# RN8XXX_V2 register map
File version: 1.0
Registers are 32-bit, read-write, reset 0x0 unless marked. A register's access mark holds for its fields unless they carry their own. Offsets are from the block's base; [hi:lo] are bit positions; {n}, {i} and the like mark numbered series; 'fields as' and 'values as' point back to an identical list.

## SYSTEM_CONTROL
Base 0x40034000
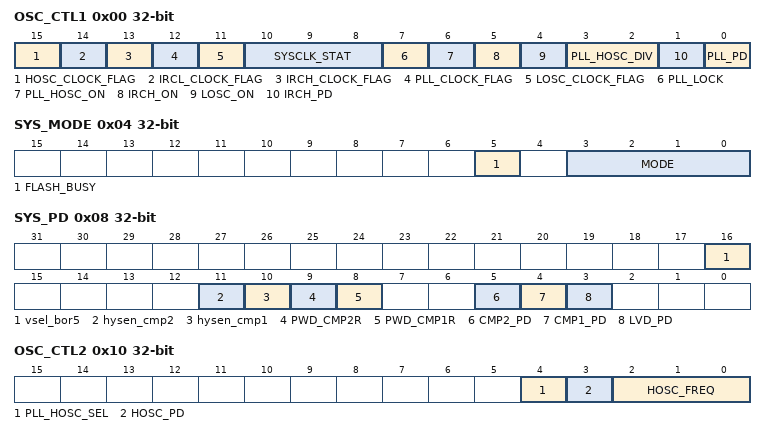
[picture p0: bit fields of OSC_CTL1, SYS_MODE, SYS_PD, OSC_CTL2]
0x00 OSC_CTL1 — system oscillator control No.1
  [15] HOSC_CLOCK_FLAG ro — HOSC on status
    0=off (HOSC stops); 1=on (HOSC running)
  [14] IRCL_CLOCK_FLAG ro — IRCL on status
    0=off (IRCL stops); 1=on (IRCL running)
  [13] IRCH_CLOCK_FLAG ro — IRCH on status
    0=off (IRCH stops); 1=on (IRCH running)
  [12] PLL_CLOCK_FLAG ro — PLL on status
    0=off (PLL stops); 1=on (PLL running)
  [11] LOSC_CLOCK_FLAG ro — LOSC on status
    0=off (LOSC stops); 1=on (LOSC running)
  [10:8] SYSCLK_STAT ro — system clock selection status
    0=7.8432MHz (system clock running at 7.8432MHz); 1=3.6864MHz (system clock running at 3.6864MHz); 2=1.8432MHz (system clock running at 1.8432MHz); 3=32.768KHz (system clock running at 32.768KHz); 4=14.7456MHz (system clock running at 14.7456MHz); 5=29.4912MHz (system clock running at 29.4912MHz)
  [7] PLL_LOCK ro — PLL locked status
    0=not_locked (PLL hasn't locked yet); 1=locked (PLL locked)
  [6] PLL_HOSC_ON ro — system clock indicator as external high-frequence oscillator or internal PLL
    0=not_PLL_HOSC (PLL_HOSC isn't used as system clock); 1=PLL_HOSC (PLL_HOSC used as system clock)
  [5] IRCH_ON ro — system clock indicator as internal RC oscillator
    0=not_IRCH (IRCH isn't used as system clock); 1=IRCH (IRCH used as system clock)
  [4] LOSC_ON ro — system clock indicator as external low-frequence oscillator
    0=not_LOSC (losc isn't used as system clock); 1=LOSC (losc used as system clock)
  [3:2] PLL_HOSC_DIV — system clock divisor(applicable for high frequency mode(PLL or HOSC))
    0=use PLL or HOSC as system clock; 1=1/2x (use 1/2 fold of PLL or HOSC as system clock); 2=1/4x (use 1/4 fold of PLL or HOSC as system clock); 3=1/8x (use 1/8 fold of PLL or HOSC as system clock)
  [1] IRCH_PD — internal RC oscillator (1.8432MHz) enbale
    1=disable IRCH; 0=enable IRCH
  [0] PLL_PD — PLL enable
    1=disable PLL; 0=enable PLL
0x04 SYS_MODE — system mode control
  [5] FLASH_BUSY ro
    0=idle (no outstanding FLASH transaction.safe to switch system mode); 1=pending FLASH transaction.forbidden to switch system mode
  [3:0] MODE — system mode switch
    4=HCM (switch to HCM mode); 2=RCM (switch to RCM mode); 1=LCM (switch to LCM mode)
0x08 SYS_PD — system power-down control
  [16] vsel_bor5
    0=2.5v_2.2v (bor5 threshold 0); 1=2.1v_1.8v (bor5 threshold 1)
  [11] hysen_cmp2 — CMP2 hysteresis switch
    0=off (close hysteresis of cmp2); 1=on (open hysteresis of cmp2)
  [10] hysen_cmp1 — CMP1 hysteresis switch
    0=off (close hysteresis of cmp1); 1=on (open hysteresis of cmp1)
  [9] PWD_CMP2R — CMP2 pull down resistor power switch
    0=on (600K pull down resistor power on); 1=off (power off)
  [8] PWD_CMP1R — CMP1 pull down resistor power switch
    0=on (600K pull down resistor power on); 1=off (power off)
  [5] CMP2_PD — Comparator No.2 power switch
    0=on (power on); 1=off (power off)
  [4] CMP1_PD — comparator No.1 power switch
    0=on (power on); 1=off (power off)
  [3] LVD_PD — LVD power switch
    0=on (power on); 1=off (power off)
0x10 OSC_CTL2 — oscillator control2
  [4] PLL_HOSC_SEL — PLL or HOSC selection
    0=PLL (select PLL as system clock); 1=HOSC (select HOSC as system clock)
  [3] HOSC_PD — HOSC power switch
    0=on (power on); 1=off (power off)
  [2:0] HOSC_FREQ — HOSC frequency selection
    0=7.3728MHz (HOSC running at 7.3728MHz); 1=14.7456MHz (HOSC running at 14.7456MHz); 2=reserved (do not use); 3=29.4912MHz (HOSC running at 29.4912MHz(Enhanced drive mode))
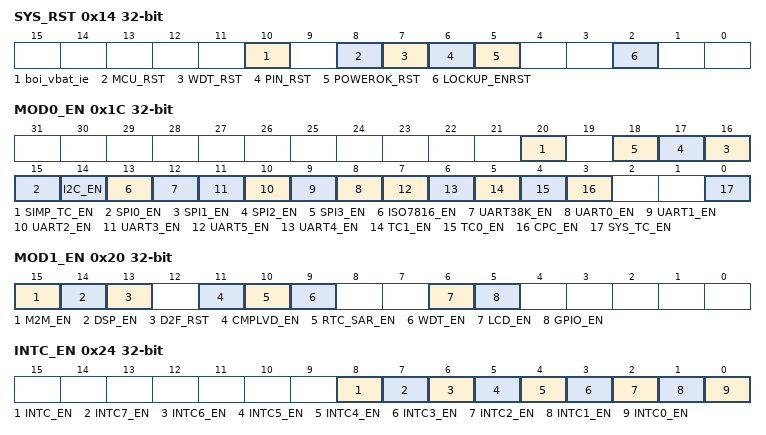
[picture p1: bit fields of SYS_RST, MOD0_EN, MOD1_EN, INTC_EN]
0x14 SYS_RST — system reset
  [10] boi_vbat_ie — vbat area power down interrupt control
    0=disable vbat power down interrupt; 1=enable vbat power down interrupt
  [8] MCU_RST — CPU reset flag(software or LOCKUP)
    0=no (no outstanding CPU reset); 1=yes (pending CPU reset)
  [7] WDT_RST — WDT reset flag
    0=no (no outstanding WDT reset); 1=yes (pending WDT reset)
  [6] PIN_RST — external pin reset flag
    0=no (no outstanding external pin reset); 1=yes (pending external pin reset)
  [5] POWEROK_RST write-1-clears — power-on reset flag
    0=no (no outstanding power-on reset); 1=yes (pending power-on reset)
  [2] LOCKUP_ENRST — LOCKUP reset enable
    0=disable (do not issue system reset on LOCKUP); 1=enable (issue system reset on LOCKUP)
0x18 MAP_CTRL — system control
  [2:0] REMAP — address remap
    0=normal (FLASH mapped at address 0); 1=1/2 FLASH switch (FLASH mapped at address 1/2 (2nd FLASH at 0x0, 1st FLASH at 0x4000 and bootload at 0)); 2=SRAM (FLASH switch mapping address with SRAM(FLASH at 0x10000000 and SRAM at 0)); 4=1/2 memory capacity (FLASH mapped at address 1/2 total memory capacity(only support less than 512KB))
0x1C MOD0_EN — module enable0
  [20] SIMP_TC_EN — SIMP_TC enable
    0=disable (module disabled and clock stop); 1=enable (module enabled and clock start)
  [n+15] SPI{n}_EN (n=0..3) — SPI{n} enable
    values as SIMP_TC_EN
  [14] I2C_EN — I2C enable
    values as SIMP_TC_EN
  [13] ISO7816_EN — ISO7816 enable
    values as SIMP_TC_EN
  [12] UART38K_EN — UART 38KHz infra-red moduling clock enable
    0=disable (clock stop); 1=enable (clock start)
  [n+8] UART{n}_EN (n=0..3) — UART{n} enable
    values as SIMP_TC_EN
  [7] UART5_EN — UART5 enable
    values as SIMP_TC_EN
  [6] UART4_EN — UART5 enable
    values as SIMP_TC_EN
  [5] TC1_EN — TC1 enable
    values as SIMP_TC_EN
  [4] TC0_EN — TC0 enable
    values as SIMP_TC_EN
  [3] CPC_EN — CPC enable
    values as SIMP_TC_EN
  [0] SYS_TC_EN — SYS_TC enable
    values as SIMP_TC_EN
0x20 MOD1_EN — module1 enable
  [all] fields
    values as MOD0_EN.SIMP_TC_EN
  [15] M2M_EN — M2M enable
  [14] DSP_EN — DSP enable
  [13] D2F_RST — D2F enable
  [11] CMPLVD_EN — CMPLVD enable
  [10] RTC_SAR_EN — RTC SAR enable
  [9] WDT_EN — WDT enable
  [6] LCD_EN — LCD enable
  [5] GPIO_EN — GPIO enable
0x24 INTC_EN — INTC enable
  [8] INTC_EN — INTC enable
    values as MOD0_EN.SIMP_TC_EN
  [7] INTC7_EN — INTC channel No.7 enable
    0=disable (channel disabled and clock stop); 1=enable (channel enabled and clock start)
  [6] INTC6_EN — INTC channel No.6 enable
    values as INTC7_EN
  [5] INTC5_EN — INTC channel No.5 enable
    values as INTC7_EN
  [4] INTC4_EN — INTC channel No.4 enable
    values as INTC7_EN
  [3] INTC3_EN — INTC channel No.3 enable
    values as INTC7_EN
  [2] INTC2_EN — INTC channel No.2 enable
    values as INTC7_EN
  [1] INTC1_EN — INTC channel No.1 enable
    values as INTC7_EN
  [0] INTC0_EN — INTC channel No.0 enable
    values as INTC7_EN
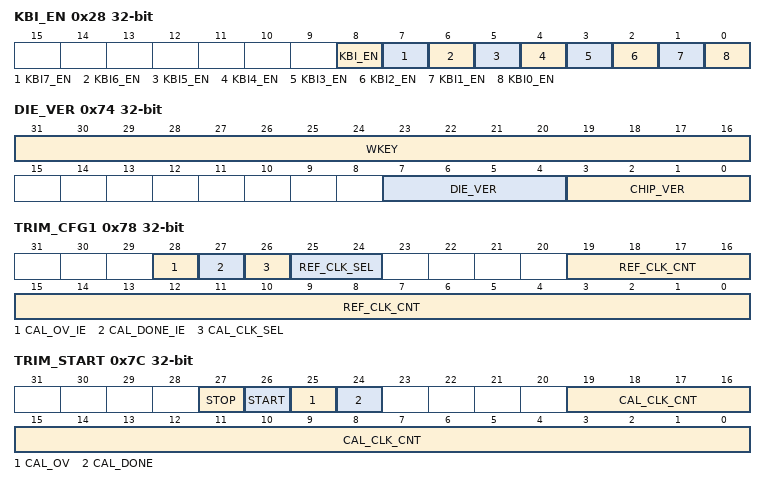
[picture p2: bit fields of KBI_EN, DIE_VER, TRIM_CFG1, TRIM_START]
0x28 KBI_EN — KBI enable
  [8] KBI_EN — KBI enable
    values as MOD0_EN.SIMP_TC_EN
  [7] KBI7_EN — KBI channel No.7 enable
    values as INTC_EN.INTC7_EN
  [6] KBI6_EN — KBI channel No.6 enable
    values as INTC_EN.INTC7_EN
  [5] KBI5_EN — KBI channel No.5 enable
    values as INTC_EN.INTC7_EN
  [4] KBI4_EN — KBI channel No.4 enable
    values as INTC_EN.INTC7_EN
  [3] KBI3_EN — KBI channel No.3 enable
    values as INTC_EN.INTC7_EN
  [2] KBI2_EN — KBI channel No.2 enable
    values as INTC_EN.INTC7_EN
  [1] KBI1_EN — KBI channel No.1 enable
    values as INTC_EN.INTC7_EN
  [0] KBI0_EN — KBI channel No.0 enable
    values as INTC_EN.INTC7_EN
0x2C CHIP_ID
  [15:0] CHIP_ID ro
0x30 SYS_PS — system control register set access protection
  [7:0] SYS_PSW
    0=protected (all system control register set are read-only); 1=accessable (all system control register set are writable)
0x34 IRFR_CTL — infra-red modulation clock divisor
  [5:0] IRFR_CYCLE — infra-red modulation clock divisor(only for RC mode). IRFR=rch_frequency/(4*divisor)
0x74 DIE_VER
  [31:16] WKEY wo — write key
  [7:4] DIE_VER
  [3:0] CHIP_VER
0x78 TRIM_CFG1 — clock trim configuration register
  [28] CAL_OV_IE — calculation overflow interrupt configuration
    0=interrupt disable (disable clock trim module overflow interrupt); 1=interrupt enable (enable clock trim module overflow interrupt)
  [27] CAL_DONE_IE — calculation down interrupt configuration
    0=interrupt disable (disable clock trim module interrupt); 1=interrupt enable (enable clock trim module interrupt)
  [26] CAL_CLK_SEL — calculate clock selection
    0=RCH (select RCH as calculate clock); 1=RCL (select RCL as calculate clock)
  [25:24] REF_CLK_SEL — reference clock selection
    0=LOSC (select LOSC as reference clock); 1=HOSC (select HOSC as reference clock); 2=RCH (select RCH as reference clock); 3=low power (clock trim module enter low power mode)
  [19:0] REF_CLK_CNT — reference clock counter value
0x7C TRIM_START — clock trim start register
  [27] STOP
    0=no operation; 1=stop counter
  [26] START
    0=no operation; 1=start counter (cleared auto while counter down)
  [25] CAL_OV
    1=clock trim counter overflow (clear to 0 by write 1); 0=clock trim counter not overflow
  [24] CAL_DONE
    1=clock trim counter finish (clear to 0 by write 1); 0=clock trim counter not finish
  [19:0] CAL_CLK_CNT ro — calculate clock counter value
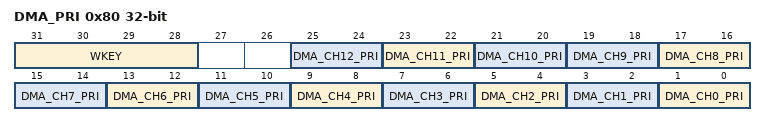
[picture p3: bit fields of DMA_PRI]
0x80 DMA_PRI — DMA priority register
  [31:28] WKEY — write key (0xE)
  [25:24] DMA_CH12_PRI — DMA CH12: CPU priority setting
    0=lowest priority (DMA lowest priority); 1=low priority (DMA low priority); 2=high priority (DMA high priority); 3=highest  priority (DMA highest priority)
  [23:22] DMA_CH11_PRI — DMA CH11: M2M priority setting
    values as DMA_CH12_PRI
  [21:20] DMA_CH10_PRI — DMA CH10: DSP priority setting
    values as DMA_CH12_PRI
  [2n+1:2n] DMA_CH{n}_PRI (n=4..9) — DMA CH{n}: UART{n-4} priority setting
    values as DMA_CH12_PRI
  [2n+1:2n] DMA_CH{n}_PRI (n=0..3) — DMA CH{n}: SPI{n} priority setting
    values as DMA_CH12_PRI
0xF0 UID0
0xF4 UID1
